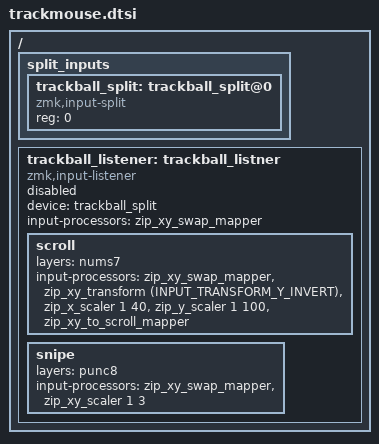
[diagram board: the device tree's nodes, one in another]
#include <dt-bindings/zmk/input_transform.h>
#include <input/processors.dtsi>

// DEFINE LAYERS
#define cmac0    0
#define qmac1    1
#define cwin2    2
#define qwin3    3
#define maus4    4
#define arro5    5
#define calc6    6
#define nums7    7
#define punc8    8
#define fkey9    9

/{
    split_inputs {
        #address-cells = <1>;
        #size-cells = <0>;

        trackball_split: trackball_split@0 {
            compatible = "zmk,input-split";
            reg = <0>;
        };
    };
    
        trackball_listener: trackball_listner {
        compatible = "zmk,input-listener";
        device = <&trackball_split>;
        status = "disabled";
        input-processors = <&zip_xy_swap_mapper>;
        scroll {
        layers = <nums7>;
        input-processors =  <&zip_xy_swap_mapper>, <&zip_xy_transform (INPUT_TRANSFORM_Y_INVERT)>, <&zip_x_scaler 1 40>, <&zip_y_scaler 1 100>, <&zip_xy_to_scroll_mapper>;
    };
        snipe {
        layers = <punc8>;
        input-processors = <&zip_xy_swap_mapper>, <&zip_xy_scaler 1 3>;
    };
 
  };
};
